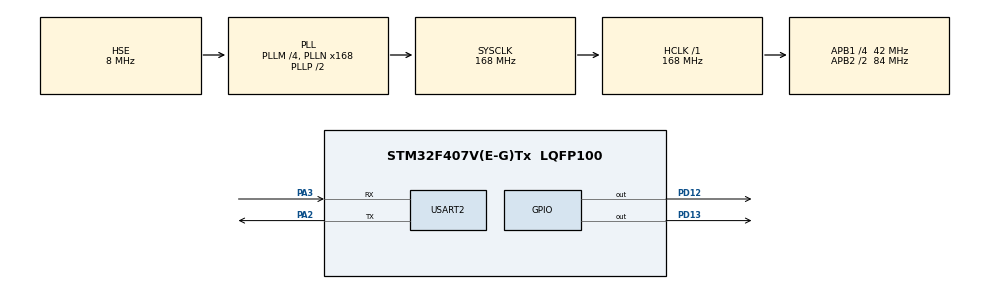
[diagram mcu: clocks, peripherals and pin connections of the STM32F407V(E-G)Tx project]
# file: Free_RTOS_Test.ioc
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FREERTOS.INCLUDE_vTaskDelayUntil=1
FREERTOS.Tasks01=defaultTask,0,128,StartDefaultTask,Default;Task02,0,128,Task2_init,Default
Mcu.Family=STM32F4
Mcu.Name=STM32F407V(E-G)Tx
Mcu.Package=LQFP100
NVIC.PriorityGroup=NVIC_PRIORITYGROUP_4
NVIC.TIM1_UP_TIM10_IRQn=true\:0\:0\:false\:false\:true
NVIC.TimeBase=TIM1_UP_TIM10_IRQn
NVIC.TimeBaseIP=TIM1
PA2.Mode=Asynchronous
PA2.Signal=USART2_TX
PA3.Mode=Asynchronous
PA3.Signal=USART2_RX
PD12.GPIO_ModeDefaultOutputPP=GPIO_MODE_OUTPUT_PP
PD12.GPIO_PuPd=GPIO_NOPULL
PD12.GPIO_Speed=GPIO_SPEED_FREQ_VERY_HIGH
PD12.PinState=GPIO_PIN_RESET
PD12.Signal=GPIO_Output
PD13.GPIO_ModeDefaultOutputPP=GPIO_MODE_OUTPUT_PP
PD13.GPIO_PuPd=GPIO_NOPULL
PD13.GPIO_Speed=GPIO_SPEED_FREQ_VERY_HIGH
PD13.PinState=GPIO_PIN_RESET
PD13.Signal=GPIO_Output
PH0-OSC_IN.Mode=HSE-External-Oscillator
PH0-OSC_IN.Signal=RCC_OSC_IN
PH1-OSC_OUT.Mode=HSE-External-Oscillator
PH1-OSC_OUT.Signal=RCC_OSC_OUT
ProjectManager.HeapSize=0x200
ProjectManager.StackSize=0x400
ProjectManager.TargetToolchain=MDK-ARM V5
RCC.48MHZClocksFreq_Value=84000000
RCC.AHBFreq_Value=168000000
RCC.APB1CLKDivider=RCC_HCLK_DIV4
RCC.APB1Freq_Value=42000000
RCC.APB1TimCLKDivider=1
RCC.APB1TimFreq_Value=42000000
RCC.APB2CLKDivider=RCC_HCLK_DIV2
RCC.APB2Freq_Value=84000000
RCC.APB2TimCLKDivider=1
RCC.APB2TimFreq_Value=84000000
RCC.CortexFreq_Value=168000000
RCC.HCLKFreq_Value=168000000
RCC.HSE_VALUE=8000000
RCC.HSI_VALUE=16000000
RCC.LSE_VALUE=32768
RCC.PLLM=4
RCC.PLLN=168
RCC.PLLSourceVirtual=RCC_PLLSOURCE_HSE
RCC.SYSCLKFreq_VALUE=168000000
RCC.SYSCLKSource=RCC_SYSCLKSOURCE_PLLCLK
RCC.VCOOutputFreq_Value=336000000
VP_FREERTOS_VS_ENABLE.Mode=Enabled
VP_SYS_VS_tim1.Mode=TIM1
board=Free_RTOS_Test

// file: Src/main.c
#include "stm32f4xx_hal.h"
#include "cmsis_os.h"
#include "stdio.h"

UART_HandleTypeDef huart2;

osThreadId    defaultTaskHandle;
osThreadId    Task02Handle;
osThreadId 		TaskHighHandle;
osSemaphoreId BinSemHandle;

/* USER CODE BEGIN PV */
/* Private variables ---------------------------------------------------------*/

/* USER CODE END PV */

void SystemClock_Config(void);
static void MX_GPIO_Init(void);
static void MX_USART2_UART_Init(void);
void StartDefaultTask(void const * argument);
void Task2_init(void const * argument);
void TaskHigh_init(void const * argument);

/* USER CODE BEGIN PFP */
/* Private function prototypes -----------------------------------------------*/
void send_data_DefaultTask(void);
void send_data_Task02(void);

/* USER CODE END PFP */

int main(void)
{

  /* MCU Configuration----------------------------------------------------------*/

  /* Reset of all peripherals, Initializes the Flash interface and the Systick. */
  HAL_Init();

  /* Configure the system clock */
  SystemClock_Config();

  /* Initialize all configured peripherals */
  MX_GPIO_Init();
  MX_USART2_UART_Init();

  /* USER CODE BEGIN RTOS_SEMAPHORES */
	osSemaphoreDef(BinSem);
  BinSemHandle = osSemaphoreCreate(osSemaphore(BinSem), 1);
  /* USER CODE END RTOS_SEMAPHORES */

  /* Create the thread(s) */
  /* definition and creation of defaultTask */
  osThreadDef(defaultTask, StartDefaultTask, osPriorityBelowNormal, 0, 128);
  defaultTaskHandle = osThreadCreate(osThread(defaultTask), NULL);

  /* definition and creation of Task02 */
  osThreadDef(Task02, Task2_init, osPriorityNormal, 0, 128);
  Task02Handle = osThreadCreate(osThread(Task02), NULL);

	/* definition and creation of TaskHigh */
  osThreadDef(TaskHigh, TaskHigh_init, osPriorityAboveNormal, 0, 128);
	TaskHighHandle = osThreadCreate(osThread(TaskHigh), NULL);

  /* Start scheduler */
  osKernelStart();

  /* We should never get here as control is now taken by the scheduler */

  /* Infinite loop */
  /* USER CODE BEGIN WHILE */
  while (1)
  {
  }
  /* USER CODE END 3 */

}
void send_data_DefaultTask(void)
{
	uint8_t data_send_defaultTask[] = "This is default task\r";
	HAL_UART_Transmit(&huart2, data_send_defaultTask, sizeof(data_send_defaultTask), 500);
}
void send_data_Task02(void)
{
	uint8_t data_send_Task02[] = "This is task2\r";
	HAL_UART_Transmit(&huart2, data_send_Task02, sizeof(data_send_Task02), 500);
}

/** System Clock Configuration
*/
void SystemClock_Config(void)
{

  RCC_OscInitTypeDef RCC_OscInitStruct;
  RCC_ClkInitTypeDef RCC_ClkInitStruct;

  __HAL_RCC_PWR_CLK_ENABLE();

  __HAL_PWR_VOLTAGESCALING_CONFIG(PWR_REGULATOR_VOLTAGE_SCALE1);

  RCC_OscInitStruct.OscillatorType = RCC_OSCILLATORTYPE_HSE;
  RCC_OscInitStruct.HSEState = RCC_HSE_ON;
  RCC_OscInitStruct.PLL.PLLState = RCC_PLL_ON;
  RCC_OscInitStruct.PLL.PLLSource = RCC_PLLSOURCE_HSE;
  RCC_OscInitStruct.PLL.PLLM = 4;
  RCC_OscInitStruct.PLL.PLLN = 168;
  RCC_OscInitStruct.PLL.PLLP = RCC_PLLP_DIV2;
  RCC_OscInitStruct.PLL.PLLQ = 4;
  HAL_RCC_OscConfig(&RCC_OscInitStruct);

  RCC_ClkInitStruct.ClockType = RCC_CLOCKTYPE_HCLK|RCC_CLOCKTYPE_SYSCLK
                              |RCC_CLOCKTYPE_PCLK1|RCC_CLOCKTYPE_PCLK2;
  RCC_ClkInitStruct.SYSCLKSource = RCC_SYSCLKSOURCE_PLLCLK;
  RCC_ClkInitStruct.AHBCLKDivider = RCC_SYSCLK_DIV1;
  RCC_ClkInitStruct.APB1CLKDivider = RCC_HCLK_DIV4;
  RCC_ClkInitStruct.APB2CLKDivider = RCC_HCLK_DIV2;
  HAL_RCC_ClockConfig(&RCC_ClkInitStruct, FLASH_LATENCY_5);

  HAL_SYSTICK_Config(HAL_RCC_GetHCLKFreq()/1000);

  HAL_SYSTICK_CLKSourceConfig(SYSTICK_CLKSOURCE_HCLK);

  /* SysTick_IRQn interrupt configuration */
  HAL_NVIC_SetPriority(SysTick_IRQn, 15, 0);
}

/* USART2 init function */
void MX_USART2_UART_Init(void)
{

  huart2.Instance = USART2;
  huart2.Init.BaudRate = 115200;
  huart2.Init.WordLength = UART_WORDLENGTH_8B;
  huart2.Init.StopBits = UART_STOPBITS_1;
  huart2.Init.Parity = UART_PARITY_NONE;
  huart2.Init.Mode = UART_MODE_TX_RX;
  huart2.Init.HwFlowCtl = UART_HWCONTROL_NONE;
  huart2.Init.OverSampling = UART_OVERSAMPLING_16;
  HAL_UART_Init(&huart2);

}

/** Configure pins as
        * Analog
        * Input
        * Output
        * EVENT_OUT
        * EXTI
*/
void MX_GPIO_Init(void)
{

  GPIO_InitTypeDef GPIO_InitStruct;

  /* GPIO Ports Clock Enable */
  __HAL_RCC_GPIOH_CLK_ENABLE();
  __HAL_RCC_GPIOD_CLK_ENABLE();
	__HAL_RCC_GPIOA_CLK_ENABLE();

  /*Configure GPIO pin Output Level */
  HAL_GPIO_WritePin(GPIOD, GPIO_PIN_12|GPIO_PIN_13, GPIO_PIN_RESET);

  /*Configure GPIO pins : PD12, PD13 */
  GPIO_InitStruct.Pin = GPIO_PIN_12|GPIO_PIN_13;
  GPIO_InitStruct.Mode = GPIO_MODE_OUTPUT_PP;
  GPIO_InitStruct.Pull = GPIO_NOPULL;
  GPIO_InitStruct.Speed = GPIO_SPEED_FREQ_HIGH;
  HAL_GPIO_Init(GPIOD, &GPIO_InitStruct);

	/*Config PA0*/
	GPIO_InitStruct.Pin = GPIO_PIN_0;
  GPIO_InitStruct.Mode = GPIO_MODE_INPUT;
  GPIO_InitStruct.Pull = GPIO_NOPULL;
	GPIO_InitStruct.Speed = GPIO_SPEED_FREQ_HIGH;
  HAL_GPIO_Init(GPIOA, &GPIO_InitStruct);

}

/* StartDefaultTask function */
void StartDefaultTask(void const * argument)
{

  /* USER CODE BEGIN 5 */
  /* Infinite loop */
  for(;;)
  {
		//send_data_DefaultTask();
		printf("Task Default\n");
		HAL_GPIO_TogglePin(GPIOD, GPIO_PIN_12);
    osDelay(1000);
  }
  /* USER CODE END 5 */
}

/* Task2_init function */
void Task2_init(void const * argument)
{
	/*uint8_t count2 = 0;
	while(1)
	{
		printf(" count2 = %d\n", count2++);
		osDelay(2000);
	}*/
  /* USER CODE END Task2_init */
	while(1)
	{
		printf("Normal is waiting Semaphore\n");
		osSemaphoreWait(BinSemHandle, osWaitForever);

		printf("Normal Task have Bin Semaphore\n");

		while( (HAL_GPIO_ReadPin(GPIOA, GPIO_PIN_0)==0) );

		printf("Normal Task release semaphore\n");
		osSemaphoreRelease(BinSemHandle);

		osDelay(1000);
	}
}

/* TaskHigh_init function */
void TaskHigh_init(void const * argument)
{
	/*uint8_t indexHigh = 0;

  for(;;)
  {
		//send_data_TaskHigh();
		printf("	HIGH = %d\n", indexHigh++);
		HAL_GPIO_TogglePin(GPIOD, GPIO_PIN_13);
		if(indexHigh == 4)
		{
			printf("	Suspend default task\n");
			osThreadSuspend(defaultTaskHandle);
		}
		if(indexHigh == 6)
		{
			printf(" 	Resume default task\n");
			osThreadResume(defaultTaskHandle);
		}
		if(indexHigh == 8)
		{
			uint32_t PreWakeTime = osKernelSysTick();
			osDelayUntil(&PreWakeTime, 2000);
		}
		osDelay(2000);
 }*/
 while(1)
 {
	 printf("High Task is waiting semaphore\n");
	 osSemaphoreWait(BinSemHandle, osWaitForever);

	 printf("High Task have semaphore\n");

	 printf("High Task release semaphore\n");
	 osSemaphoreRelease(BinSemHandle);
	 osDelay(1000);
 }
}

/************************ (C) COPYRIGHT STMicroelectronics *****END OF FILE****/
